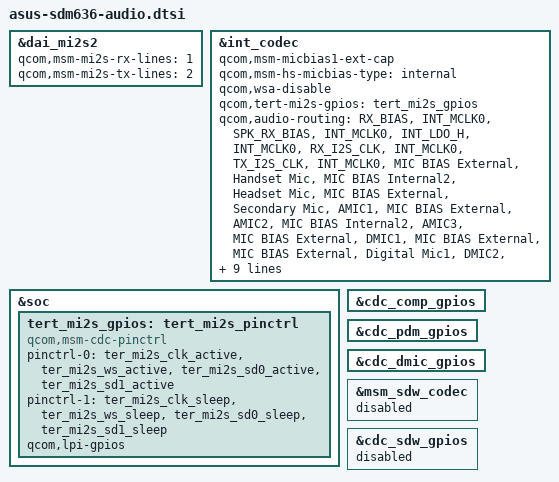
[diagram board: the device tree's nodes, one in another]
// SPDX-License-Identifier: GPL-2.0
// Copyright (C) 2021 Atom-X-Devs < https://www.github.com/Atom-X-Devs >

// asus msm-audo.dtsi specific changes
&dai_mi2s2 {
	qcom,msm-mi2s-rx-lines = <1>;
	qcom,msm-mi2s-tx-lines = <2>;
};

&int_codec {
	/delete-property/ qcom,msm-micbias2-ext-cap;
	qcom,msm-micbias1-ext-cap;
	qcom,msm-hs-micbias-type = "internal";
	qcom,wsa-disable;
	qcom,tert-mi2s-gpios = <&tert_mi2s_gpios>;
	qcom,audio-routing =
		"RX_BIAS", "INT_MCLK0",
		"SPK_RX_BIAS", "INT_MCLK0",
		"INT_LDO_H", "INT_MCLK0",
		"RX_I2S_CLK", "INT_MCLK0",
		"TX_I2S_CLK", "INT_MCLK0",
		"MIC BIAS External", "Handset Mic",
		"MIC BIAS Internal2", "Headset Mic",
		"MIC BIAS External", "Secondary Mic",
		"AMIC1", "MIC BIAS External",
		"AMIC2", "MIC BIAS Internal2",
		"AMIC3", "MIC BIAS External",
		"DMIC1", "MIC BIAS External",
		"MIC BIAS External", "Digital Mic1",
		"DMIC2", "MIC BIAS External",
		"MIC BIAS External", "Digital Mic2",
		"DMIC3", "MIC BIAS External",
		"MIC BIAS External", "Digital Mic3",
		"DMIC4", "MIC BIAS External",
		"MIC BIAS External", "Digital Mic4",
		"SpkrLeft IN", "SPK1 OUT",
		"SpkrRight IN", "SPK2 OUT",
		"PDM_IN_RX1", "PDM_OUT_RX1",
		"PDM_IN_RX2", "PDM_OUT_RX2",
		"PDM_IN_RX3", "PDM_OUT_RX3",
		"ADC1_IN", "ADC1_OUT",
		"ADC2_IN", "ADC2_OUT",
		"ADC3_IN", "ADC3_OUT";

};

// asus sdm660-audo.dtsi specific changes
&soc {
	tert_mi2s_gpios: tert_mi2s_pinctrl {
		compatible = "qcom,msm-cdc-pinctrl";
		pinctrl-names = "aud_active", "aud_sleep";
		pinctrl-0 = <&ter_mi2s_clk_active &ter_mi2s_ws_active
			&ter_mi2s_sd0_active &ter_mi2s_sd1_active>;
		pinctrl-1 = <&ter_mi2s_clk_sleep &ter_mi2s_ws_sleep
			&ter_mi2s_sd0_sleep &ter_mi2s_sd1_sleep>;
		qcom,lpi-gpios;
	};
};

// asus sdm660-external-codec.dtsi specific changes
&cdc_comp_gpios {
	status = "okay";
};

&cdc_pdm_gpios {
	status = "okay";
};

&cdc_dmic_gpios {
	status = "okay";
};

// asus sdm660-internal-codec.dtsi specific diff
&msm_sdw_codec {
	status = "disabled";
};

&cdc_sdw_gpios {
	status = "disabled";
};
